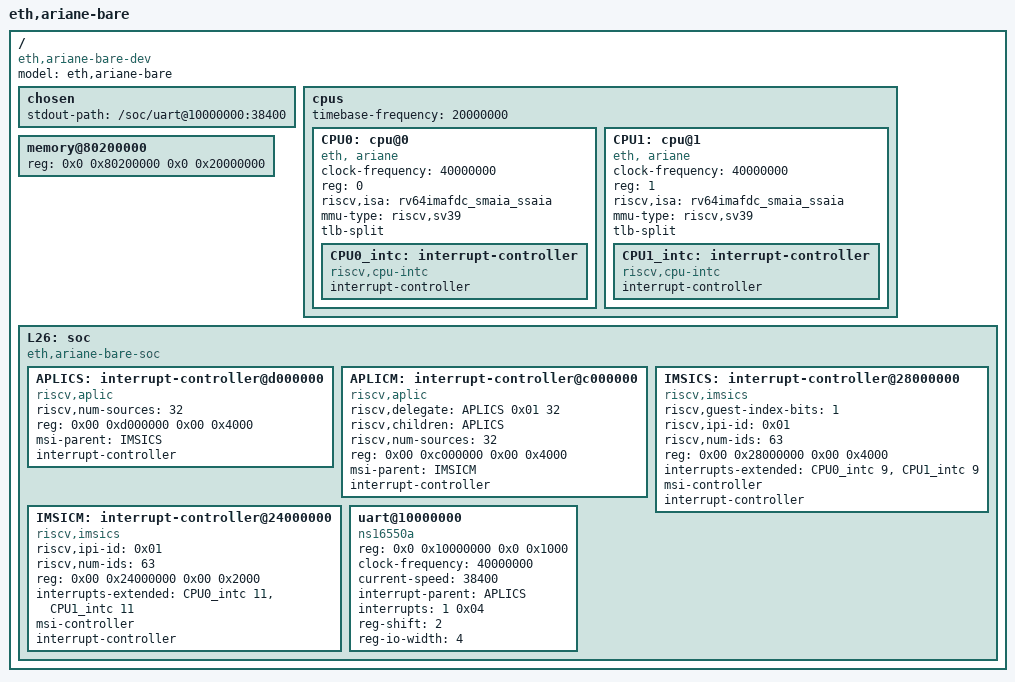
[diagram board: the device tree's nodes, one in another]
/dts-v1/;

/ {
  #address-cells = <2>;
  #size-cells = <2>;
  compatible = "eth,ariane-bare-dev";
  model = "eth,ariane-bare";
  chosen {
    stdout-path = "/soc/uart@10000000:38400";
  };
  cpus {
    #address-cells = <1>;
    #size-cells = <0>;
    timebase-frequency = <20000000>; // 20 MHz
    CPU0: cpu@0 {
      clock-frequency = <40000000>; // 40 MHz
      device_type = "cpu";
      reg = <0>;
      status = "okay";
      compatible = "eth, ariane", "riscv";
      riscv,isa = "rv64imafdc_smaia_ssaia";
      mmu-type = "riscv,sv39";
      tlb-split;
      // HLIC - hart local interrupt controller
      CPU0_intc: interrupt-controller {
        #interrupt-cells = <1>;
        interrupt-controller;
        compatible = "riscv,cpu-intc";
      };
    };
    CPU1: cpu@1 {
      clock-frequency = <40000000>; // 40 MHz
      device_type = "cpu";
      reg = <1>;
      status = "okay";
      compatible = "eth, ariane", "riscv";
      riscv,isa = "rv64imafdc_smaia_ssaia";
      mmu-type = "riscv,sv39";
      tlb-split;
      // HLIC - hart local interrupt controller
      CPU1_intc: interrupt-controller {
        #interrupt-cells = <1>;
        interrupt-controller;
        compatible = "riscv,cpu-intc";
      };
    };
  };
  memory@80200000 {
    device_type = "memory";
    reg = <0x0 0x80200000 0x0 0x20000000>;
  };
  L26: soc {
    #address-cells = <2>;
    #size-cells = <2>;
    compatible = "eth,ariane-bare-soc", "simple-bus";
    ranges;

    APLICS: interrupt-controller@d000000 {
			riscv,num-sources = <32>;
			reg = <0x00 0xd000000 0x00 0x4000>;
			msi-parent = <&IMSICS>;
			interrupt-controller;
			#interrupt-cells = <0x02>;
			compatible = "riscv,aplic";
		};

		APLICM: interrupt-controller@c000000 {
			riscv,delegate = <&APLICS 0x01 32>;
			riscv,children = <&APLICS>;
			riscv,num-sources = <32>;
			reg = <0x00 0xc000000 0x00 0x4000>;
			msi-parent = <&IMSICM>;
			interrupt-controller;
			#interrupt-cells = <0x02>;
			compatible = "riscv,aplic";
		};

		IMSICS: interrupt-controller@28000000 {
      riscv,guest-index-bits = <1>;
			riscv,ipi-id = <0x01>;
			riscv,num-ids = <63>;
			reg = <0x00 0x28000000 0x00 0x4000>;
			interrupts-extended = <&CPU0_intc 9>, <&CPU1_intc 9>;
			msi-controller;
			interrupt-controller;
			#interrupt-cells = <0x01>;
			compatible = "riscv,imsics";
		};

		IMSICM: interrupt-controller@24000000 {
			riscv,ipi-id = <0x01>;
			riscv,num-ids = <63>;
			reg = <0x00 0x24000000 0x00 0x2000>;
			interrupts-extended = <&CPU0_intc 11>, <&CPU1_intc 11>;
			msi-controller;
			interrupt-controller;
			#interrupt-cells = <0x01>;
			compatible = "riscv,imsics";
		};

    uart@10000000 {
      compatible = "ns16550a";
      reg = <0x0 0x10000000 0x0 0x1000>;
      clock-frequency = <40000000>;
      current-speed = <38400>;
      interrupt-parent = <&APLICS>;
      interrupts = <1 0x04>;
      reg-shift = <2>; // regs are spaced on 32 bit boundary
      reg-io-width = <4>; // only 32-bit access are supported
    };
  };
};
